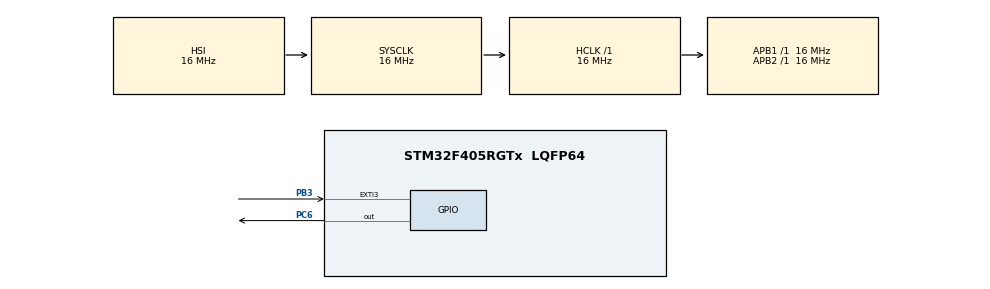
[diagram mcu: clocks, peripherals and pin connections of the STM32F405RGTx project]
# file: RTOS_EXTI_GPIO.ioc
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FREERTOS.Tasks01=defaultTask,0,128,StartDefaultTask,Default,NULL,Dynamic,NULL,NULL
FREERTOS.configLIBRARY_MAX_SYSCALL_INTERRUPT_PRIORITY=5
Mcu.Family=STM32F4
Mcu.Name=STM32F405RGTx
Mcu.Package=LQFP64
NVIC.EXTI3_IRQn=true\:0\:0\:false\:false\:true\:false\:true\:true\:true
NVIC.PriorityGroup=NVIC_PRIORITYGROUP_4
PA13.Mode=Serial_Wire
PA13.Signal=SYS_JTMS-SWDIO
PA14.Mode=Serial_Wire
PA14.Signal=SYS_JTCK-SWCLK
PB3.Signal=GPXTI3
PC14-OSC32_IN.Mode=LSE-External-Oscillator
PC14-OSC32_IN.Signal=RCC_OSC32_IN
PC15-OSC32_OUT.Mode=LSE-External-Oscillator
PC15-OSC32_OUT.Signal=RCC_OSC32_OUT
PC6.Signal=GPIO_Output
PH0-OSC_IN.Mode=HSE-External-Oscillator
PH0-OSC_IN.Signal=RCC_OSC_IN
PH1-OSC_OUT.Mode=HSE-External-Oscillator
PH1-OSC_OUT.Signal=RCC_OSC_OUT
ProjectManager.HeapSize=0x200
ProjectManager.StackSize=0x400
ProjectManager.TargetToolchain=STM32CubeIDE
RCC.AHBFreq_Value=16000000
RCC.APB1Freq_Value=16000000
RCC.APB2Freq_Value=16000000
RCC.CortexFreq_Value=16000000
RCC.HSE_VALUE=25000000
RCC.HSI_VALUE=16000000
RCC.SYSCLKFreq_VALUE=16000000
RCC.VCOOutputFreq_Value=192000000
VP_FREERTOS_VS_CMSIS_V1.Mode=CMSIS_V1
board=custom

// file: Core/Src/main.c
/* USER CODE BEGIN Header */
/**
  ******************************************************************************
  * @file           : main.c
  * @brief          : Main program body
  ******************************************************************************
  * @attention
  *
  * Copyright (c) 2025 STMicroelectronics.
  * All rights reserved.
  *
  * This software is licensed under terms that can be found in the LICENSE file
  * in the root directory of this software component.
  * If no LICENSE file comes with this software, it is provided AS-IS.
  *
  ******************************************************************************
  */
/* USER CODE END Header */
#include "main.h"
#include "FreeRTOS.h"
#include "task.h"

/* USER CODE BEGIN PD */
TaskHandle_t Task1Handle;
/* USER CODE END PD */

void SystemClock_Config(void);
static void MX_GPIO_Init(void);
void LEDTask( void * pvParameters);

int main(void)
{

  /* MCU Configuration--------------------------------------------------------*/

  /* Reset of all peripherals, Initializes the Flash interface and the Systick. */
  HAL_Init();

  /* Configure the system clock */
  SystemClock_Config();

  /* Initialize all configured peripherals */
  MX_GPIO_Init();

  /* Create the thread(s) */
  /* definition and creation of defaultTask */
  xTaskCreate(LEDTask,"LED",128,NULL,1,&Task1Handle);

  /* Start scheduler */
  vTaskStartScheduler();
  /* We should never get here as control is now taken by the scheduler */

  /* Infinite loop */
  while (1)
  {

  }
}

void SystemClock_Config(void)
{
  RCC_OscInitTypeDef RCC_OscInitStruct = {0};
  RCC_ClkInitTypeDef RCC_ClkInitStruct = {0};

  /** Configure the main internal regulator output voltage
  */
  __HAL_RCC_PWR_CLK_ENABLE();
  __HAL_PWR_VOLTAGESCALING_CONFIG(PWR_REGULATOR_VOLTAGE_SCALE1);

  /** Initializes the RCC Oscillators according to the specified parameters
  * in the RCC_OscInitTypeDef structure.
  */
  RCC_OscInitStruct.OscillatorType = RCC_OSCILLATORTYPE_HSI;
  RCC_OscInitStruct.HSIState = RCC_HSI_ON;
  RCC_OscInitStruct.HSICalibrationValue = RCC_HSICALIBRATION_DEFAULT;
  RCC_OscInitStruct.PLL.PLLState = RCC_PLL_NONE;
  if (HAL_RCC_OscConfig(&RCC_OscInitStruct) != HAL_OK)
  {
    Error_Handler();
  }

  /** Initializes the CPU, AHB and APB buses clocks
  */
  RCC_ClkInitStruct.ClockType = RCC_CLOCKTYPE_HCLK|RCC_CLOCKTYPE_SYSCLK
                              |RCC_CLOCKTYPE_PCLK1|RCC_CLOCKTYPE_PCLK2;
  RCC_ClkInitStruct.SYSCLKSource = RCC_SYSCLKSOURCE_HSI;
  RCC_ClkInitStruct.AHBCLKDivider = RCC_SYSCLK_DIV1;
  RCC_ClkInitStruct.APB1CLKDivider = RCC_HCLK_DIV1;
  RCC_ClkInitStruct.APB2CLKDivider = RCC_HCLK_DIV1;

  if (HAL_RCC_ClockConfig(&RCC_ClkInitStruct, FLASH_LATENCY_0) != HAL_OK)
  {
    Error_Handler();
  }
}

static void MX_GPIO_Init(void)
{
  GPIO_InitTypeDef GPIO_InitStruct = {0};

  /* GPIO Ports Clock Enable */
  __HAL_RCC_GPIOC_CLK_ENABLE();
  __HAL_RCC_GPIOH_CLK_ENABLE();
  __HAL_RCC_GPIOA_CLK_ENABLE();
  __HAL_RCC_GPIOB_CLK_ENABLE();

  /*Configure GPIO pin Output Level */
  HAL_GPIO_WritePin(GPIOC, GPIO_PIN_6, GPIO_PIN_RESET);

  /*Configure GPIO pin : PC6 */
  GPIO_InitStruct.Pin = GPIO_PIN_6;
  GPIO_InitStruct.Mode = GPIO_MODE_OUTPUT_PP;
  GPIO_InitStruct.Pull = GPIO_NOPULL;
  GPIO_InitStruct.Speed = GPIO_SPEED_FREQ_LOW;
  HAL_GPIO_Init(GPIOC, &GPIO_InitStruct);

  /*Configure GPIO pin : PB3 */
  GPIO_InitStruct.Pin = GPIO_PIN_3;
  GPIO_InitStruct.Mode = GPIO_MODE_IT_RISING;
  GPIO_InitStruct.Pull = GPIO_NOPULL;
  HAL_GPIO_Init(GPIOB, &GPIO_InitStruct);
  /* EXTI interrupt init*/
  HAL_NVIC_SetPriorityGrouping(NVIC_PRIORITYGROUP_4);
  HAL_NVIC_SetPriority(EXTI3_IRQn,6, 0);
  HAL_NVIC_EnableIRQ(EXTI3_IRQn);

}

/* USER CODE BEGIN 4 */
void HAL_GPIO_EXTI_Callback(uint16_t GPIO_Pin)
{
	 BaseType_t xHigherPriorityTaskWoken = pdFALSE;

	    // Notify Task1 from ISR
	    vTaskNotifyGiveFromISR(Task1Handle, &xHigherPriorityTaskWoken);

	    portYIELD_FROM_ISR(xHigherPriorityTaskWoken);
}
/* USER CODE END 4 */

void LEDTask(void * pvParameters)
{
	for(;;)
	{
		//Wait for Notification set
	    ulTaskNotifyTake(pdTRUE,portMAX_DELAY);
	    //Toogle GPIO
	    HAL_GPIO_TogglePin(GPIOC, GPIO_PIN_6);
	}
}

void Error_Handler(void)
{
  __disable_irq();
  while (1)
  {
  }
}
